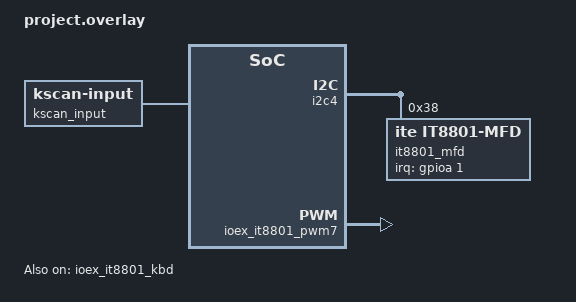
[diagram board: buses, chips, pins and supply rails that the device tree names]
/* Copyright 2023 The ChromiumOS Authors
 * Use of this source code is governed by a BSD-style license that can be
 * found in the LICENSE file.
 */

 /* Main devictree overlay for the it8xxx2_evb project */
#include "adc.dtsi"
#include "fan.dtsi"
#include "gpio.dtsi"
#include "gpio.dtsi"
#include "i2c.dtsi"
#include "interrupts.dtsi"
#include "pwm.dtsi"
#include "shi.dtsi"

&i2c4 {
	status = "okay";

	it8801_mfd: it8801@38 {
		compatible = "ite,it8801-mfd";
		reg = <0x38>;
		irq-gpios = <&gpioa 1 0>;
	};
};

#include <ite/it8801-common-cfg.dtsi>

&ioex_it8801_kbd {
	status = "okay";
	mfdctrl = <&kso18_gp01_default>;
	kso-mapping = <0 1 20 3 4 5 6 17 18 16 15 11 12>;
	row-size = <8>;
	col-size = <13>;

	kscan_input: kscan-input {
		compatible = "zephyr,kscan-input";
	};
};

&ioex_it8801_pwm7 {
	status = "okay";
};

